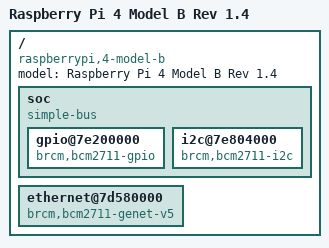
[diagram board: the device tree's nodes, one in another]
/dts-v1/;

/ {
	model = "Raspberry Pi 4 Model B Rev 1.4";
	compatible = "raspberrypi,4-model-b", "brcm,bcm2711";

	soc {
		compatible = "simple-bus";

		gpio@7e200000 {
			compatible = "brcm,bcm2711-gpio";
		};

		i2c@7e804000 {
			compatible = "brcm,bcm2711-i2c", "brcm,bcm2835-i2c";
		};
	};

	ethernet@7d580000 {
		compatible = "brcm,bcm2711-genet-v5";
	};
};
